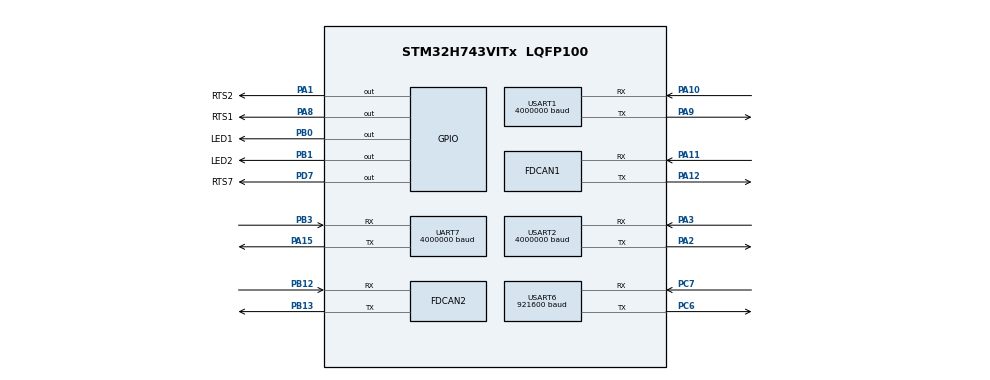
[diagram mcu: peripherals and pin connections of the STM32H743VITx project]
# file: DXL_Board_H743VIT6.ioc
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CORTEX_M7.CPU_ICache=Enabled
CORTEX_M7.default_mode_Activation=0
Dma.Request0=USART1_RX
Dma.Request1=USART1_TX
Dma.Request2=USART2_RX
Dma.Request3=USART2_TX
Dma.Request4=UART7_RX
Dma.Request5=UART7_TX
Dma.UART7_RX.4.Direction=DMA_PERIPH_TO_MEMORY
Dma.UART7_RX.4.EventEnable=DISABLE
Dma.UART7_RX.4.FIFOMode=DMA_FIFOMODE_DISABLE
Dma.UART7_RX.4.Instance=DMA1_Stream4
Dma.UART7_RX.4.MemDataAlignment=DMA_MDATAALIGN_BYTE
Dma.UART7_RX.4.MemInc=DMA_MINC_ENABLE
Dma.UART7_RX.4.Mode=DMA_NORMAL
Dma.UART7_RX.4.PeriphDataAlignment=DMA_PDATAALIGN_BYTE
Dma.UART7_RX.4.PeriphInc=DMA_PINC_DISABLE
Dma.UART7_RX.4.Polarity=HAL_DMAMUX_REQ_GEN_RISING
Dma.UART7_RX.4.Priority=DMA_PRIORITY_LOW
Dma.UART7_RX.4.RequestNumber=1
Dma.UART7_RX.4.SignalID=NONE
Dma.UART7_RX.4.SyncEnable=DISABLE
Dma.UART7_RX.4.SyncPolarity=HAL_DMAMUX_SYNC_NO_EVENT
Dma.UART7_RX.4.SyncRequestNumber=1
Dma.UART7_RX.4.SyncSignalID=NONE
Dma.UART7_TX.5.Direction=DMA_MEMORY_TO_PERIPH
Dma.UART7_TX.5.EventEnable=DISABLE
Dma.UART7_TX.5.FIFOMode=DMA_FIFOMODE_DISABLE
Dma.UART7_TX.5.Instance=DMA1_Stream5
Dma.UART7_TX.5.MemDataAlignment=DMA_MDATAALIGN_BYTE
Dma.UART7_TX.5.MemInc=DMA_MINC_ENABLE
Dma.UART7_TX.5.Mode=DMA_NORMAL
Dma.UART7_TX.5.PeriphDataAlignment=DMA_PDATAALIGN_BYTE
Dma.UART7_TX.5.PeriphInc=DMA_PINC_DISABLE
Dma.UART7_TX.5.Polarity=HAL_DMAMUX_REQ_GEN_RISING
Dma.UART7_TX.5.Priority=DMA_PRIORITY_LOW
Dma.UART7_TX.5.RequestNumber=1
Dma.UART7_TX.5.SignalID=NONE
Dma.UART7_TX.5.SyncEnable=DISABLE
Dma.UART7_TX.5.SyncPolarity=HAL_DMAMUX_SYNC_NO_EVENT
Dma.UART7_TX.5.SyncRequestNumber=1
Dma.UART7_TX.5.SyncSignalID=NONE
Dma.USART1_RX.0.Direction=DMA_PERIPH_TO_MEMORY
Dma.USART1_RX.0.EventEnable=DISABLE
Dma.USART1_RX.0.FIFOMode=DMA_FIFOMODE_DISABLE
Dma.USART1_RX.0.Instance=DMA1_Stream0
Dma.USART1_RX.0.MemDataAlignment=DMA_MDATAALIGN_BYTE
Dma.USART1_RX.0.MemInc=DMA_MINC_ENABLE
Dma.USART1_RX.0.Mode=DMA_NORMAL
Dma.USART1_RX.0.PeriphDataAlignment=DMA_PDATAALIGN_BYTE
Dma.USART1_RX.0.PeriphInc=DMA_PINC_DISABLE
Dma.USART1_RX.0.Polarity=HAL_DMAMUX_REQ_GEN_RISING
Dma.USART1_RX.0.Priority=DMA_PRIORITY_LOW
Dma.USART1_RX.0.RequestNumber=1
Dma.USART1_RX.0.SignalID=NONE
Dma.USART1_RX.0.SyncEnable=DISABLE
Dma.USART1_RX.0.SyncPolarity=HAL_DMAMUX_SYNC_NO_EVENT
Dma.USART1_RX.0.SyncRequestNumber=1
Dma.USART1_RX.0.SyncSignalID=NONE
Dma.USART1_TX.1.Direction=DMA_MEMORY_TO_PERIPH
Dma.USART1_TX.1.EventEnable=DISABLE
Dma.USART1_TX.1.FIFOMode=DMA_FIFOMODE_DISABLE
Dma.USART1_TX.1.Instance=DMA1_Stream1
Dma.USART1_TX.1.MemDataAlignment=DMA_MDATAALIGN_BYTE
Dma.USART1_TX.1.MemInc=DMA_MINC_ENABLE
Dma.USART1_TX.1.Mode=DMA_NORMAL
Dma.USART1_TX.1.PeriphDataAlignment=DMA_PDATAALIGN_BYTE
Dma.USART1_TX.1.PeriphInc=DMA_PINC_DISABLE
Dma.USART1_TX.1.Polarity=HAL_DMAMUX_REQ_GEN_RISING
Dma.USART1_TX.1.Priority=DMA_PRIORITY_LOW
Dma.USART1_TX.1.RequestNumber=1
Dma.USART1_TX.1.SignalID=NONE
Dma.USART1_TX.1.SyncEnable=DISABLE
Dma.USART1_TX.1.SyncPolarity=HAL_DMAMUX_SYNC_NO_EVENT
Dma.USART1_TX.1.SyncRequestNumber=1
Dma.USART1_TX.1.SyncSignalID=NONE
Dma.USART2_RX.2.Direction=DMA_PERIPH_TO_MEMORY
Dma.USART2_RX.2.EventEnable=DISABLE
Dma.USART2_RX.2.FIFOMode=DMA_FIFOMODE_DISABLE
Dma.USART2_RX.2.Instance=DMA1_Stream2
Dma.USART2_RX.2.MemDataAlignment=DMA_MDATAALIGN_BYTE
Dma.USART2_RX.2.MemInc=DMA_MINC_ENABLE
Dma.USART2_RX.2.Mode=DMA_NORMAL
Dma.USART2_RX.2.PeriphDataAlignment=DMA_PDATAALIGN_BYTE
Dma.USART2_RX.2.PeriphInc=DMA_PINC_DISABLE
Dma.USART2_RX.2.Polarity=HAL_DMAMUX_REQ_GEN_RISING
Dma.USART2_RX.2.Priority=DMA_PRIORITY_LOW
Dma.USART2_RX.2.RequestNumber=1
Dma.USART2_RX.2.SignalID=NONE
Dma.USART2_RX.2.SyncEnable=DISABLE
Dma.USART2_RX.2.SyncPolarity=HAL_DMAMUX_SYNC_NO_EVENT
Dma.USART2_RX.2.SyncRequestNumber=1
Dma.USART2_RX.2.SyncSignalID=NONE
Dma.USART2_TX.3.Direction=DMA_MEMORY_TO_PERIPH
Dma.USART2_TX.3.EventEnable=DISABLE
Dma.USART2_TX.3.FIFOMode=DMA_FIFOMODE_DISABLE
Dma.USART2_TX.3.Instance=DMA1_Stream3
Dma.USART2_TX.3.MemDataAlignment=DMA_MDATAALIGN_BYTE
Dma.USART2_TX.3.MemInc=DMA_MINC_ENABLE
Dma.USART2_TX.3.Mode=DMA_NORMAL
Dma.USART2_TX.3.PeriphDataAlignment=DMA_PDATAALIGN_BYTE
Dma.USART2_TX.3.PeriphInc=DMA_PINC_DISABLE
Dma.USART2_TX.3.Polarity=HAL_DMAMUX_REQ_GEN_RISING
Dma.USART2_TX.3.Priority=DMA_PRIORITY_LOW
Dma.USART2_TX.3.RequestNumber=1
Dma.USART2_TX.3.SignalID=NONE
Dma.USART2_TX.3.SyncEnable=DISABLE
Dma.USART2_TX.3.SyncPolarity=HAL_DMAMUX_SYNC_NO_EVENT
Dma.USART2_TX.3.SyncRequestNumber=1
Dma.USART2_TX.3.SyncSignalID=NONE
FDCAN1.AutoRetransmission=ENABLE
FDCAN1.CalculateBaudRateNominal=1000000
FDCAN1.CalculateTimeBitNominal=1000
FDCAN1.CalculateTimeQuantumNominal=125.0
FDCAN1.DataSyncJumpWidth=4
FDCAN1.DataTimeSeg1=11
FDCAN1.DataTimeSeg2=4
FDCAN1.ExtFiltersNbr=1
FDCAN1.FrameFormat=FDCAN_FRAME_FD_NO_BRS
FDCAN1.Mode=FDCAN_MODE_NORMAL
FDCAN1.NominalPrescaler=10
FDCAN1.NominalSyncJumpWidth=2
FDCAN1.NominalTimeSeg1=5
FDCAN1.ProtocolException=ENABLE
FDCAN1.RxBufferSize=FDCAN_DATA_BYTES_64
FDCAN1.RxBuffersNbr=0
FDCAN1.RxFifo0ElmtSize=FDCAN_DATA_BYTES_48
FDCAN1.RxFifo0ElmtsNbr=24
FDCAN1.RxFifo1ElmtSize=FDCAN_DATA_BYTES_64
FDCAN1.StdFiltersNbr=2
FDCAN1.TxBuffersNbr=0
FDCAN1.TxElmtSize=FDCAN_DATA_BYTES_48
FDCAN1.TxEventsNbr=3
FDCAN1.TxFifoQueueElmtsNbr=8
FDCAN2.AutoRetransmission=DISABLE
FDCAN2.CalculateBaudRateNominal=1000000
FDCAN2.CalculateTimeBitNominal=1000
FDCAN2.CalculateTimeQuantumNominal=125.0
FDCAN2.DataPrescaler=2
FDCAN2.DataSyncJumpWidth=10
FDCAN2.DataTimeSeg1=29
FDCAN2.DataTimeSeg2=10
FDCAN2.ExtFiltersNbr=1
FDCAN2.MessageRAMOffset=1280
FDCAN2.NominalPrescaler=10
FDCAN2.NominalSyncJumpWidth=2
FDCAN2.NominalTimeSeg1=5
FDCAN2.NominalTimeSeg2=2
FDCAN2.ProtocolException=ENABLE
FDCAN2.RxFifo1ElmtsNbr=64
FDCAN2.StdFiltersNbr=1
FDCAN2.TxFifoQueueElmtsNbr=8
Mcu.Family=STM32H7
Mcu.Name=STM32H743VITx
Mcu.Package=LQFP100
NVIC.DMA1_Stream0_IRQn=true\:1\:0\:true\:false\:true\:false\:true\:true
NVIC.DMA1_Stream1_IRQn=true\:1\:0\:true\:false\:true\:false\:true\:true
NVIC.DMA1_Stream2_IRQn=true\:1\:0\:true\:false\:true\:false\:true\:true
NVIC.DMA1_Stream3_IRQn=true\:1\:0\:true\:false\:true\:false\:true\:true
NVIC.DMA1_Stream4_IRQn=true\:1\:0\:true\:false\:true\:false\:true\:true
NVIC.DMA1_Stream5_IRQn=true\:1\:0\:true\:false\:true\:false\:true\:true
NVIC.FDCAN1_IT0_IRQn=true\:1\:1\:true\:false\:true\:true\:true\:true
NVIC.FDCAN2_IT0_IRQn=true\:1\:1\:true\:false\:true\:true\:true\:true
NVIC.PriorityGroup=NVIC_PRIORITYGROUP_3
NVIC.TIM2_IRQn=true\:2\:0\:true\:false\:true\:true\:true\:true
NVIC.TIM3_IRQn=true\:2\:1\:true\:false\:true\:true\:true\:true
NVIC.UART7_IRQn=true\:1\:0\:true\:false\:true\:true\:true\:true
NVIC.USART1_IRQn=true\:1\:0\:true\:false\:true\:true\:true\:true
NVIC.USART2_IRQn=true\:1\:0\:true\:false\:true\:true\:true\:true
PA1.GPIO_Label=RTS2
PA1.GPIO_PuPd=GPIO_PULLDOWN
PA1.GPIO_Speed=GPIO_SPEED_FREQ_LOW
PA1.Signal=GPIO_Output
PA10.Mode=Asynchronous
PA10.Signal=USART1_RX
PA11.GPIO_PuPd=GPIO_PULLUP
PA11.GPIO_Speed=GPIO_SPEED_FREQ_VERY_HIGH
PA11.Mode=FDCAN_Activate
PA11.Signal=FDCAN1_RX
PA12.GPIO_PuPd=GPIO_PULLUP
PA12.GPIO_Speed=GPIO_SPEED_FREQ_VERY_HIGH
PA12.Mode=FDCAN_Activate
PA12.Signal=FDCAN1_TX
PA15\ (JTDI).Mode=Asynchronous
PA15\ (JTDI).Signal=UART7_TX
PA2.Mode=Asynchronous
PA2.Signal=USART2_TX
PA3.Mode=Asynchronous
PA3.Signal=USART2_RX
PA8.GPIO_Label=RTS1
PA8.GPIO_PuPd=GPIO_PULLDOWN
PA8.GPIO_Speed=GPIO_SPEED_FREQ_LOW
PA8.Signal=GPIO_Output
PA9.Mode=Asynchronous
PA9.Signal=USART1_TX
PB0.GPIO_Label=LED1
PB0.GPIO_Speed=GPIO_SPEED_FREQ_LOW
PB0.Signal=GPIO_Output
PB1.GPIO_Label=LED2
PB1.Signal=GPIO_Output
PB12.GPIO_PuPd=GPIO_PULLUP
PB12.GPIO_Speed=GPIO_SPEED_FREQ_VERY_HIGH
PB12.Mode=FDCAN_Activate
PB12.Signal=FDCAN2_RX
PB13.GPIO_PuPd=GPIO_PULLUP
PB13.GPIO_Speed=GPIO_SPEED_FREQ_VERY_HIGH
PB13.Mode=FDCAN_Activate
PB13.Signal=FDCAN2_TX
PB3\ (JTDO/TRACESWO).Mode=Asynchronous
PB3\ (JTDO/TRACESWO).Signal=UART7_RX
PC6.Mode=Asynchronous
PC6.Signal=USART6_TX
PC7.Mode=Asynchronous
PC7.Signal=USART6_RX
PD7.GPIO_Label=RTS7
PD7.GPIO_PuPd=GPIO_PULLDOWN
PD7.Signal=GPIO_Output
PH0-OSC_IN\ (PH0).Mode=HSE-External-Oscillator
PH0-OSC_IN\ (PH0).Signal=RCC_OSC_IN
PH1-OSC_OUT\ (PH1).Mode=HSE-External-Oscillator
PH1-OSC_OUT\ (PH1).Signal=RCC_OSC_OUT
ProjectManager.HeapSize=0x200
ProjectManager.StackSize=0x400
ProjectManager.TargetToolchain=STM32CubeIDE
RCC.ADCFreq_Value=80000000
RCC.APB1Freq_Value=120000000
RCC.APB2Freq_Value=120000000
RCC.APB3Freq_Value=120000000
RCC.APB4Freq_Value=120000000
RCC.CortexFreq_Value=480000000
RCC.D1PPRE=RCC_APB3_DIV2
RCC.D2PPRE1=RCC_APB1_DIV2
RCC.D2PPRE2=RCC_APB2_DIV2
RCC.D3PPRE=RCC_APB4_DIV2
RCC.DIVM1=4
RCC.DIVN1=60
RCC.DIVN2=80
RCC.FDCANCLockSelection=RCC_FDCANCLKSOURCE_PLL2
RCC.HCLKFreq_Value=240000000
RCC.HPRE=RCC_HCLK_DIV2
RCC.HSE_VALUE=16000000
RCC.PLL2FRACN=0
RCC.PLL3FRACN=0
RCC.PLLFRACN=0
RCC.PWR_Regulator_Voltage_Scale=PWR_REGULATOR_VOLTAGE_SCALE0
RCC.ProductRev=revV
RCC.SYSCLKFreq_VALUE=480000000
RCC.SYSCLKSource=RCC_SYSCLKSOURCE_PLLCLK
RCC.USBFreq_Value=480000000
TIM1.AutoReloadPreload=TIM_AUTORELOAD_PRELOAD_DISABLE
TIM1.Prescaler=240
TIM2.AutoReloadPreload=TIM_AUTORELOAD_PRELOAD_DISABLE
TIM2.Period=1000
TIM2.Prescaler=240
TIM3.AutoReloadPreload=TIM_AUTORELOAD_PRELOAD_DISABLE
TIM3.Period=5000
TIM3.Prescaler=240
TIM5.Prescaler=240
UART7.BaudRate=4000000
USART1.BaudRate=4000000
USART1.VirtualMode-Asynchronous=VM_ASYNC
USART2.BaudRate=4000000
USART2.VirtualMode-Asynchronous=VM_ASYNC
USART6.BaudRate=921600
USART6.VirtualMode=VM_ASYNC
VP_TIM1_VS_ClockSourceINT.Mode=Internal
VP_TIM2_VS_ClockSourceINT.Mode=Internal
VP_TIM3_VS_ClockSourceINT.Mode=Internal
VP_TIM5_VS_ClockSourceINT.Mode=Internal
board=custom

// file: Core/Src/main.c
/* USER CODE BEGIN Header */
/**
  ******************************************************************************
  * @file           : main.c
  * @brief          : Main program body
  ******************************************************************************
  * @attention
  *
  * Copyright (c) 2023 STMicroelectronics.
  * All rights reserved.
  *
  * This software is licensed under terms that can be found in the LICENSE file
  * in the root directory of this software component.
  * If no LICENSE file comes with this software, it is provided AS-IS.
  *
  ******************************************************************************
  */
/* USER CODE END Header */
#include "main.h"
#include "dma.h"
#include "fdcan.h"
#include "tim.h"
#include "usart.h"
#include "gpio.h"

/* USER CODE BEGIN Includes */
#include "dxl_control.h"
#include "printing.h"
/* USER CODE END Includes */

void SystemClock_Config(void);
void PeriphCommonClock_Config(void);

int main(void)
{
/* Enable the CPU Cache */

  /* Enable I-Cache---------------------------------------------------------*/
  SCB_EnableICache();

  /* MCU Configuration--------------------------------------------------------*/

  /* Reset of all peripherals, Initializes the Flash interface and the Systick. */
  HAL_Init();

  /* Configure the system clock */
  SystemClock_Config();

/* Configure the peripherals common clocks */
  PeriphCommonClock_Config();

  /* Initialize all configured peripherals */
  MX_GPIO_Init();
  MX_DMA_Init();
  MX_USART1_UART_Init();
  MX_USART2_UART_Init();
  MX_USART6_UART_Init();
  MX_FDCAN1_Init();
  MX_TIM1_Init();
  MX_TIM2_Init();
  MX_TIM3_Init();
  MX_TIM5_Init();
  MX_FDCAN2_Init();
  MX_UART7_Init();
  /* USER CODE BEGIN 2 */
  HAL_NVIC_DisableIRQ(TIM2_IRQn);
  HAL_NVIC_DisableIRQ(TIM3_IRQn);

  /* USER CODE END 2 */

  /* Infinite loop */
  /* USER CODE BEGIN WHILE */
//	printf("\n\rStarting Dynamixel control...\n\r");
	dxl_main();
  while (1)
  {
    /* USER CODE END WHILE */

    /* USER CODE BEGIN 3 */
	  printf("You shouldn't be seeing this message!\r\n");
	  HAL_Delay(1000);
  }
  /* USER CODE END 3 */
}

void SystemClock_Config(void)
{
  RCC_OscInitTypeDef RCC_OscInitStruct = {0};
  RCC_ClkInitTypeDef RCC_ClkInitStruct = {0};

  /** Supply configuration update enable
  */
  HAL_PWREx_ConfigSupply(PWR_LDO_SUPPLY);

  /** Configure the main internal regulator output voltage
  */
  __HAL_PWR_VOLTAGESCALING_CONFIG(PWR_REGULATOR_VOLTAGE_SCALE1);

  while(!__HAL_PWR_GET_FLAG(PWR_FLAG_VOSRDY)) {}

  __HAL_RCC_SYSCFG_CLK_ENABLE();
  __HAL_PWR_VOLTAGESCALING_CONFIG(PWR_REGULATOR_VOLTAGE_SCALE0);

  while(!__HAL_PWR_GET_FLAG(PWR_FLAG_VOSRDY)) {}

  /** Initializes the RCC Oscillators according to the specified parameters
  * in the RCC_OscInitTypeDef structure.
  */
  RCC_OscInitStruct.OscillatorType = RCC_OSCILLATORTYPE_HSI;
  RCC_OscInitStruct.HSIState = RCC_HSI_DIV1;
  RCC_OscInitStruct.HSICalibrationValue = RCC_HSICALIBRATION_DEFAULT;
  RCC_OscInitStruct.PLL.PLLState = RCC_PLL_ON;
  RCC_OscInitStruct.PLL.PLLSource = RCC_PLLSOURCE_HSI;
  RCC_OscInitStruct.PLL.PLLM = 4;
  RCC_OscInitStruct.PLL.PLLN = 60;
  RCC_OscInitStruct.PLL.PLLP = 2;
  RCC_OscInitStruct.PLL.PLLQ = 2;
  RCC_OscInitStruct.PLL.PLLR = 2;
  RCC_OscInitStruct.PLL.PLLRGE = RCC_PLL1VCIRANGE_3;
  RCC_OscInitStruct.PLL.PLLVCOSEL = RCC_PLL1VCOWIDE;
  RCC_OscInitStruct.PLL.PLLFRACN = 0;
  if (HAL_RCC_OscConfig(&RCC_OscInitStruct) != HAL_OK)
  {
    Error_Handler();
  }

  /** Initializes the CPU, AHB and APB buses clocks
  */
  RCC_ClkInitStruct.ClockType = RCC_CLOCKTYPE_HCLK|RCC_CLOCKTYPE_SYSCLK
                              |RCC_CLOCKTYPE_PCLK1|RCC_CLOCKTYPE_PCLK2
                              |RCC_CLOCKTYPE_D3PCLK1|RCC_CLOCKTYPE_D1PCLK1;
  RCC_ClkInitStruct.SYSCLKSource = RCC_SYSCLKSOURCE_PLLCLK;
  RCC_ClkInitStruct.SYSCLKDivider = RCC_SYSCLK_DIV1;
  RCC_ClkInitStruct.AHBCLKDivider = RCC_HCLK_DIV2;
  RCC_ClkInitStruct.APB3CLKDivider = RCC_APB3_DIV2;
  RCC_ClkInitStruct.APB1CLKDivider = RCC_APB1_DIV2;
  RCC_ClkInitStruct.APB2CLKDivider = RCC_APB2_DIV2;
  RCC_ClkInitStruct.APB4CLKDivider = RCC_APB4_DIV2;

  if (HAL_RCC_ClockConfig(&RCC_ClkInitStruct, FLASH_LATENCY_4) != HAL_OK)
  {
    Error_Handler();
  }
}

void PeriphCommonClock_Config(void)
{
  RCC_PeriphCLKInitTypeDef PeriphClkInitStruct = {0};

  /** Initializes the peripherals clock
  */
  PeriphClkInitStruct.PeriphClockSelection = RCC_PERIPHCLK_FDCAN;
  PeriphClkInitStruct.PLL2.PLL2M = 32;
  PeriphClkInitStruct.PLL2.PLL2N = 80;
  PeriphClkInitStruct.PLL2.PLL2P = 2;
  PeriphClkInitStruct.PLL2.PLL2Q = 2;
  PeriphClkInitStruct.PLL2.PLL2R = 2;
  PeriphClkInitStruct.PLL2.PLL2RGE = RCC_PLL2VCIRANGE_1;
  PeriphClkInitStruct.PLL2.PLL2VCOSEL = RCC_PLL2VCOMEDIUM;
  PeriphClkInitStruct.PLL2.PLL2FRACN = 0;
  PeriphClkInitStruct.FdcanClockSelection = RCC_FDCANCLKSOURCE_PLL2;
  if (HAL_RCCEx_PeriphCLKConfig(&PeriphClkInitStruct) != HAL_OK)
  {
    Error_Handler();
  }
}

void Error_Handler(void)
{
  __disable_irq();
  while (1)
  {
  }
}
